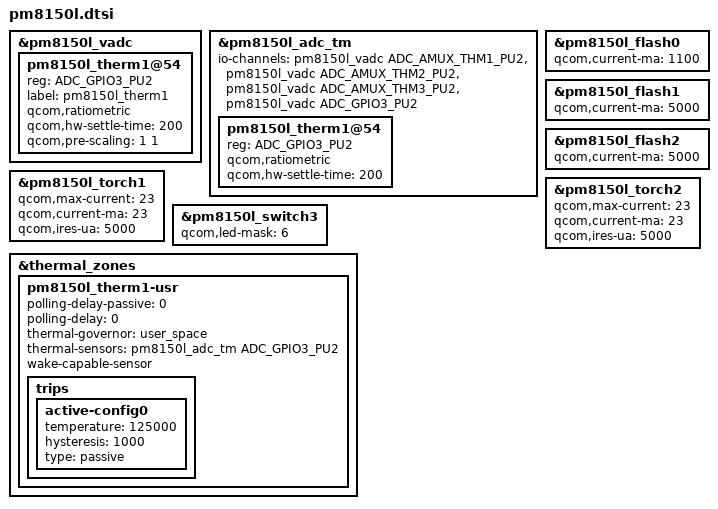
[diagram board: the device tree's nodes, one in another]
&pm8150l_vadc {
	pm8150l_therm1@54 {
		reg = <ADC_GPIO3_PU2>;
		label = "pm8150l_therm1";
		qcom,ratiometric;
		qcom,hw-settle-time = <200>;
		qcom,pre-scaling = <1 1>;
	};
};

&pm8150l_adc_tm {
	io-channels = <&pm8150l_vadc ADC_AMUX_THM1_PU2>,
			<&pm8150l_vadc ADC_AMUX_THM2_PU2>,
			<&pm8150l_vadc ADC_AMUX_THM3_PU2>,
			<&pm8150l_vadc ADC_GPIO3_PU2>;
	
	pm8150l_therm1@54 {
		reg = <ADC_GPIO3_PU2>;
		qcom,ratiometric;
		qcom,hw-settle-time = <200>;
	};
};

&pm8150l_flash0 {
    qcom,current-ma = <1100>;
};

&pm8150l_flash1 {
    qcom,current-ma = <5000>;
};

&pm8150l_flash2 {
    qcom,current-ma = <5000>;
    status = "ok";
};

&pm8150l_torch1 {
    qcom,max-current = <23>;
    qcom,current-ma = <23>;
    qcom,ires-ua = <5000>;
};

&pm8150l_torch2 {
    qcom,max-current = <23>;
    qcom,current-ma = <23>;
    qcom,ires-ua = <5000>;
    status = "ok";
};

&pm8150l_switch3 {
    qcom,led-mask = <6>;
};

&thermal_zones {
    pm8150l_therm1-usr {
        polling-delay-passive = <0>;
        polling-delay = <0>;
        thermal-governor = "user_space";
        thermal-sensors = <&pm8150l_adc_tm ADC_GPIO3_PU2>;
        wake-capable-sensor;
        trips {
            active-config0 {
                temperature = <125000>;
                hysteresis = <1000>;
                type = "passive";
            };
        };
    };
};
